VERSION "MK7 cluster DBC v2 — full reference for mk7-cluster-bench-controller"

NS_ :

BS_:

BU_: Tester Cluster Gateway EngineECU TCM ABS Airbag BCM EPS RX

VAL_TABLE_ Mode_OnOff 0 "OFF" 1 "ON" ;
VAL_TABLE_ Gear_Selector 1 "P" 2 "R" 3 "N" 4 "D" 5 "S" 6 "M" 0 "OFF" ;

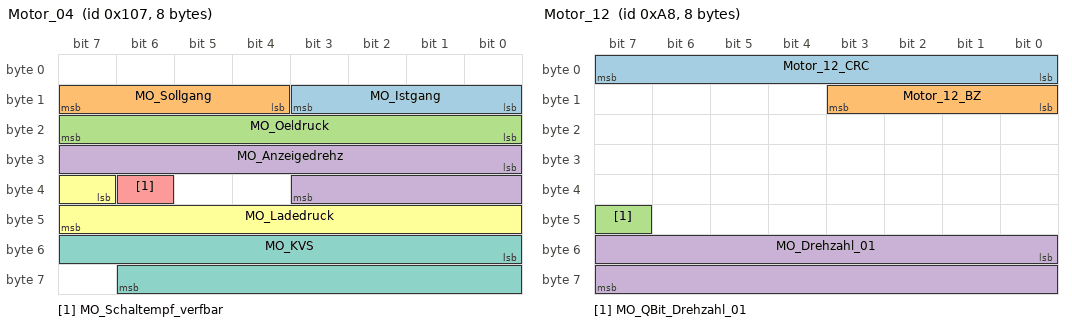
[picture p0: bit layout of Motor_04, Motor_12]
BO_ 263 Motor_04: 8 EngineECU
 SG_ MO_Istgang : 8|4@1+ (1,0) [0|15] "" Cluster
 SG_ MO_Sollgang : 12|4@1+ (1,0) [0|15] "" Cluster
 SG_ MO_Oeldruck : 16|8@1+ (0.04,0) [0|10] "Bar" Cluster
 SG_ MO_Anzeigedrehz : 24|12@1+ (3,0) [0|12282] "RPM" Cluster
 SG_ MO_Schaltempf_verfbar : 38|1@1+ (1,0) [0|1] "" Cluster
 SG_ MO_Ladedruck : 39|9@1+ (0.01,0) [0|5.1] "Bar" Cluster
 SG_ MO_KVS : 48|15@1+ (1,0) [0|32767] "uL" Cluster

BO_ 168 Motor_12: 8 EngineECU
 SG_ Motor_12_CRC : 0|8@1+ (1,0) [0|255] "" RX
 SG_ Motor_12_BZ : 8|4@1+ (1,0) [0|15] "" RX
 SG_ MO_QBit_Drehzahl_01 : 47|1@1+ (1,0) [0|1] "" RX
 SG_ MO_Drehzahl_01 : 48|16@1+ (0.25,0) [0|16383] "RPM" RX

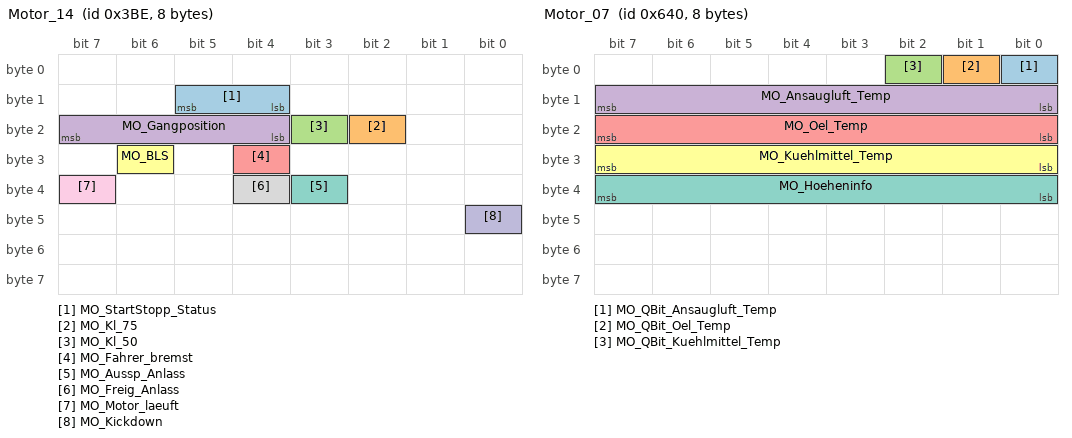
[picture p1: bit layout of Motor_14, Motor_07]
BO_ 958 Motor_14: 8 EngineECU
 SG_ MO_StartStopp_Status : 12|2@1+ (1,0) [0|3] "" Cluster
 SG_ MO_Kl_75 : 18|1@1+ (1,0) [0|1] "" Cluster
 SG_ MO_Kl_50 : 19|1@1+ (1,0) [0|1] "" Cluster
 SG_ MO_Gangposition : 20|4@1+ (1,0) [0|15] "" Cluster
 SG_ MO_Fahrer_bremst : 28|1@1+ (1,0) [0|1] "" Cluster
 SG_ MO_BLS : 30|1@1+ (1,0) [0|1] "" Cluster
 SG_ MO_Aussp_Anlass : 35|1@1+ (1,0) [0|1] "" Cluster
 SG_ MO_Freig_Anlass : 36|1@1+ (1,0) [0|1] "" Cluster
 SG_ MO_Motor_laeuft : 39|1@1+ (1,0) [0|1] "" Cluster
 SG_ MO_Kickdown : 40|1@1+ (1,0) [0|1] "" Cluster

BO_ 1600 Motor_07: 8 EngineECU
 SG_ MO_QBit_Ansaugluft_Temp : 0|1@1+ (1,0) [0|1] "" Cluster
 SG_ MO_QBit_Oel_Temp : 1|1@1+ (1,0) [0|1] "" Cluster
 SG_ MO_QBit_Kuehlmittel_Temp : 2|1@1+ (1,0) [0|1] "" Cluster
 SG_ MO_Ansaugluft_Temp : 8|8@1+ (0.75,-48) [-48|141.75] "DegC" Cluster
 SG_ MO_Oel_Temp : 16|8@1+ (1,-60) [-60|192] "DegC" Cluster
 SG_ MO_Kuehlmittel_Temp : 24|8@1+ (0.75,-48) [-48|141.75] "DegC" Cluster
 SG_ MO_Hoeheninfo : 32|8@1+ (0.00781,0) [0|1.98374] "" Cluster

BO_ 1607 Motor_09: 8 EngineECU
 SG_ MO_Coolant_Display : 0|8@1+ (1,0) [0|255] "" Cluster
 SG_ MO_E85_Sensor : 8|4@1+ (10,0) [0|100] "%" Cluster

BO_ 1601 Motor_Code_01: 8 EngineECU
 SG_ MotorCode01_CRC : 0|8@1+ (1,0) [0|255] "" Cluster
 SG_ MotorCode01_BZ : 8|4@1+ (1,0) [0|15] "" Cluster

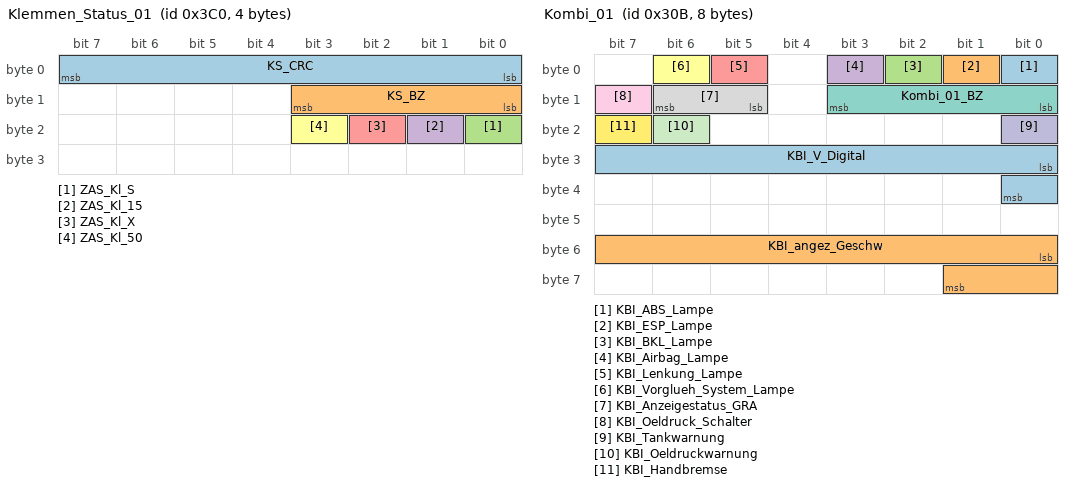
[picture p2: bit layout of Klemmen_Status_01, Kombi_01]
BO_ 960 Klemmen_Status_01: 4 Gateway
 SG_ KS_CRC : 0|8@1+ (1,0) [0|255] "" RX
 SG_ KS_BZ : 8|4@1+ (1,0) [0|15] "" RX
 SG_ ZAS_Kl_S : 16|1@1+ (1,0) [0|1] "" RX
 SG_ ZAS_Kl_15 : 17|1@1+ (1,0) [0|1] "" RX
 SG_ ZAS_Kl_X : 18|1@1+ (1,0) [0|1] "" RX
 SG_ ZAS_Kl_50 : 19|1@1+ (1,0) [0|1] "" RX

BO_ 779 Kombi_01: 8 Cluster
 SG_ KBI_ABS_Lampe : 0|1@1+ (1,0) [0|1] "" RX
 SG_ KBI_ESP_Lampe : 1|1@1+ (1,0) [0|1] "" RX
 SG_ KBI_BKL_Lampe : 2|1@1+ (1,0) [0|1] "" RX
 SG_ KBI_Airbag_Lampe : 3|1@1+ (1,0) [0|1] "" RX
 SG_ KBI_Lenkung_Lampe : 5|1@1+ (1,0) [0|1] "" RX
 SG_ KBI_Vorglueh_System_Lampe : 6|1@1+ (1,0) [0|1] "" RX
 SG_ Kombi_01_BZ : 8|4@1+ (1,0) [0|15] "" RX
 SG_ KBI_Anzeigestatus_GRA : 13|2@1+ (1,0) [0|3] "" RX
 SG_ KBI_Oeldruck_Schalter : 15|1@1+ (1,0) [0|1] "" RX
 SG_ KBI_Tankwarnung : 16|1@1+ (1,0) [0|1] "" RX
 SG_ KBI_Oeldruckwarnung : 22|1@1+ (1,0) [0|1] "" RX
 SG_ KBI_Handbremse : 23|1@1+ (1,0) [0|1] "" RX
 SG_ KBI_V_Digital : 24|9@1+ (1,0) [0|511] "km/h" RX
 SG_ KBI_angez_Geschw : 48|10@1+ (0.32,0) [0|325.12] "km/h" RX

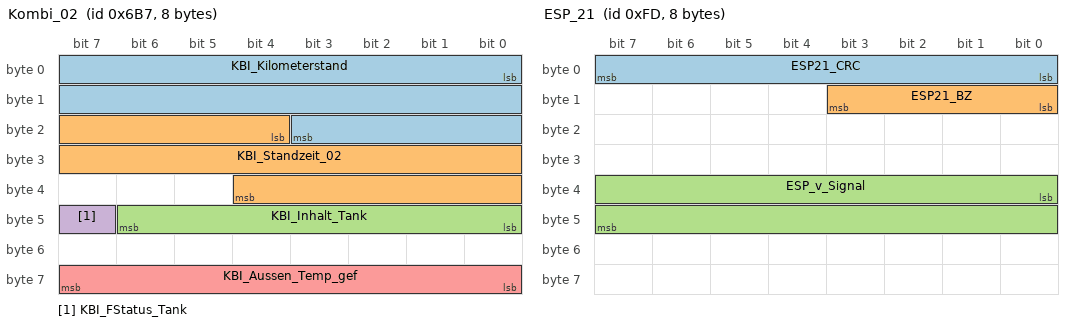
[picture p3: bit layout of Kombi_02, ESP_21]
BO_ 1719 Kombi_02: 8 Gateway
 SG_ KBI_Kilometerstand : 0|20@1+ (1,0) [0|1048573] "km" Cluster
 SG_ KBI_Standzeit_02 : 20|17@1+ (1,0) [0|131068] "s" Cluster
 SG_ KBI_Inhalt_Tank : 40|7@1+ (1,0) [0|125] "L" Cluster
 SG_ KBI_FStatus_Tank : 47|1@1+ (1,0) [0|1] "" Cluster
 SG_ KBI_Aussen_Temp_gef : 56|8@1+ (0.5,-50) [-50|75] "DegC" Cluster

BO_ 253 ESP_21: 8 ABS
 SG_ ESP21_CRC : 0|8@1+ (1,0) [0|255] "" RX
 SG_ ESP21_BZ : 8|4@1+ (1,0) [0|15] "" RX
 SG_ ESP_v_Signal : 32|16@1+ (0.01,0) [0|655.35] "km/h" RX

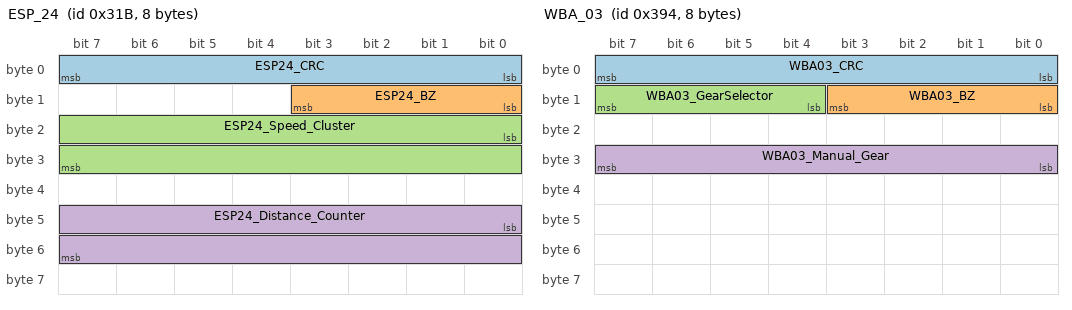
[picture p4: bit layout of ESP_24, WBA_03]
BO_ 795 ESP_24: 8 ABS
 SG_ ESP24_CRC : 0|8@1+ (1,0) [0|255] "" RX
 SG_ ESP24_BZ : 8|4@1+ (1,0) [0|15] "" RX
 SG_ ESP24_Speed_Cluster : 16|16@1+ (1,0) [0|65535] "" RX
 SG_ ESP24_Distance_Counter : 40|16@1+ (1,0) [0|65535] "" RX

BO_ 257 ESP_02: 8 ABS
 SG_ ESP02_CRC : 0|8@1+ (1,0) [0|255] "" RX
 SG_ ESP02_BZ : 8|4@1+ (1,0) [0|15] "" RX

BO_ 278 ESP_10: 8 ABS
 SG_ ESP10_CRC : 0|8@1+ (1,0) [0|255] "" RX
 SG_ ESP10_BZ : 8|4@1+ (1,0) [0|15] "" RX

BO_ 1629 ESP_20: 8 ABS
 SG_ ESP20_CRC : 0|8@1+ (1,0) [0|255] "" RX
 SG_ ESP20_BZ : 8|4@1+ (1,0) [0|15] "" RX

BO_ 798 TSK_07: 8 EngineECU
 SG_ TSK07_CRC : 0|8@1+ (1,0) [0|255] "" RX
 SG_ TSK07_BZ : 8|4@1+ (1,0) [0|15] "" RX

BO_ 810 LH_EPS_01: 8 EPS
 SG_ LHEPS01_CRC : 0|8@1+ (1,0) [0|255] "" RX
 SG_ LHEPS01_BZ : 8|4@1+ (1,0) [0|15] "" RX

BO_ 64 Airbag_01: 8 Airbag
 SG_ AB01_CRC : 0|8@1+ (1,0) [0|255] "" RX
 SG_ AB01_BZ : 8|4@1+ (1,0) [0|15] "" RX

BO_ 916 WBA_03: 8 Gateway
 SG_ WBA03_CRC : 0|8@1+ (1,0) [0|255] "" Cluster
 SG_ WBA03_BZ : 8|4@1+ (1,0) [0|15] "" Cluster
 SG_ WBA03_GearSelector : 12|4@1+ (1,0) [0|15] "" Cluster
 SG_ WBA03_Manual_Gear : 24|8@1+ (1,0) [0|9] "" Cluster

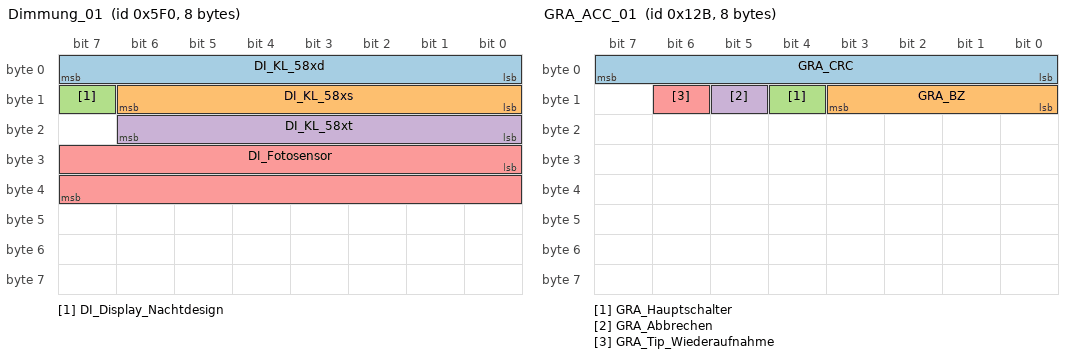
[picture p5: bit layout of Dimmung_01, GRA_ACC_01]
BO_ 1520 Dimmung_01: 8 Gateway
 SG_ DI_KL_58xd : 0|8@1+ (1,0) [0|253] "" RX
 SG_ DI_KL_58xs : 8|7@1+ (1,0) [0|100] "%" RX
 SG_ DI_Display_Nachtdesign : 15|1@1+ (1,0) [0|1] "" RX
 SG_ DI_KL_58xt : 16|7@1+ (1,0) [0|100] "%" RX
 SG_ DI_Fotosensor : 24|16@1+ (1,0) [0|65535] "" RX

BO_ 299 GRA_ACC_01: 8 Gateway
 SG_ GRA_CRC : 0|8@1+ (1,0) [0|255] "" RX
 SG_ GRA_BZ : 8|4@1+ (1,0) [0|15] "" RX
 SG_ GRA_Hauptschalter : 12|1@1+ (1,0) [0|1] "" RX
 SG_ GRA_Abbrechen : 13|1@1+ (1,0) [0|1] "" RX
 SG_ GRA_Tip_Wiederaufnahme : 14|1@1+ (1,0) [0|1] "" RX

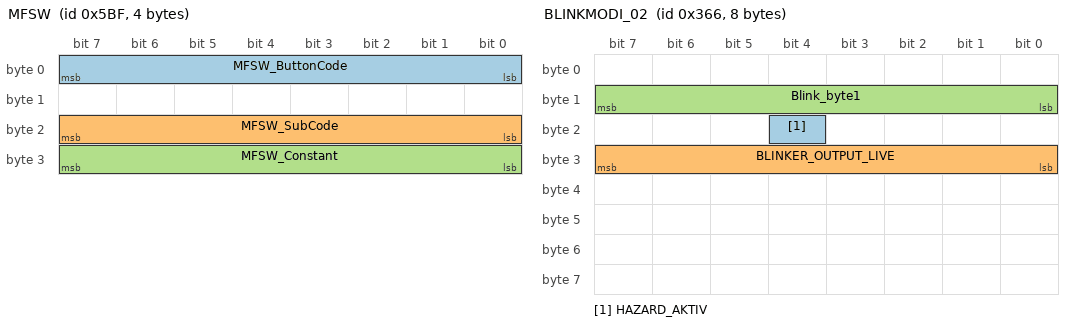
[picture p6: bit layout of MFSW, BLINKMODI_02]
BO_ 1471 MFSW: 4 Gateway
 SG_ MFSW_ButtonCode : 0|8@1+ (1,0) [0|255] "" Cluster
 SG_ MFSW_SubCode : 16|8@1+ (1,0) [0|255] "" Cluster
 SG_ MFSW_Constant : 24|8@1+ (1,0) [0|255] "" Cluster

BO_ 870 BLINKMODI_02: 8 BCM
 SG_ HAZARD_AKTIV : 20|1@1+ (1,0) [0|1] "" RX
 SG_ BLINKER_OUTPUT_LIVE : 24|8@1+ (1,0) [0|255] "" RX
 SG_ Blink_byte1 : 8|8@1+ (1,0) [0|255] "" RX

BO_ 1624 LICHT_VORNE_01: 8 BCM
 SG_ Front_HighBeam : 14|1@1+ (1,0) [0|1] "" RX
 SG_ Front_byte1_full : 8|8@1+ (1,0) [0|255] "" RX

BO_ 982 LICHT_HINTEN_01: 8 BCM
 SG_ Rear_byte1_full : 8|8@1+ (1,0) [0|255] "" RX

BO_ 1411 DOOR_STATUS_01: 8 BCM
 SG_ Door_byte0 : 0|8@1+ (1,0) [0|255] "" RX

BO_ 1505 OUTDOOR_TEMP_01: 8 Gateway
 SG_ Outdoor_byte1 : 8|8@1+ (0.5,-50) [-50|75] "DegC" RX

BO_ 1610 TPMS_01: 8 BCM
 SG_ TPMS_byte0 : 0|8@1+ (1,0) [0|255] "" RX

BO_ 1635 RKA_01: 8 BCM
 SG_ RKA_byte0 : 0|8@1+ (1,0) [0|255] "" RX

BO_ 1603 Einheiten_01: 8 Gateway
 SG_ Einheit_Speed_kmh_mph : 0|1@1+ (1,0) [0|1] "" Cluster
 SG_ Einheit_Temp_C_F : 1|1@1+ (1,0) [0|1] "" Cluster

BO_ 1716 VIN_01: 8 Gateway
 SG_ VIN_chunk_index : 0|8@1+ (1,0) [0|255] "" RX
 SG_ VIN_chunk_data : 8|56@1+ (1,0) [0|0] "" RX

CM_ BO_ 263 "Motor_04 — Engine ECU broadcast at ~50 Hz. CONFIRMED on 5G1 920 740B: bytes 3-4 LE drive cluster RPM tachometer (formula raw * 3 RPM/tick).";
CM_ BO_ 168 "Motor_12 — Engine torque + actual RPM. MQB CRC + counter required.";
CM_ BO_ 958 "Motor_14 — Engine status: gear position, engine_running flag, brake pedal, kickdown. MQB CRC + counter (constants 0xC0 from openpilot).";
CM_ BO_ 1600 "Motor_07 — Engine temps (intake, oil, COOLANT). byte 0 has QBit validity flags.";
CM_ BO_ 1607 "Motor_09 — CONFIRMED ON 5G1 920 740B AND validated against real vehicle CAN log (Alltrack 2017, May 2026). byte 0 = coolant value with linear mapping 0x80=50C → 0xED=130C (formula: temp_C = byte * 0.7339 - 43.94). Bytes 1-3 = magic 'FD FF 7F' confirmed identical on real vehicle. Bytes 4-6 = 00. byte 7 cycles between 0x13/0x18/0xC1/0x12 on real ECU (likely a counter or rolling sequence — but cluster accepts static 0xC1 too). Real ECU broadcasts at only ~2 Hz, so spoofing at 20+ Hz dominates the bus arbitration easily. Engine warmup logged: 0x86(54C) → 0xB3(87C) over 106 sec, perfectly linear with our formula. No CRC, no counter on byte 0/1.";
CM_ BO_ 1601 "Motor_Code_01 — Engine ECU heartbeat. CONFIRMED required as engine context for coolant override on 5G1 920 740B. MQB CRC with all-0x47 constants.";
CM_ BO_ 960 "Klemmen_Status_01 — CONFIRMED wakes the cluster on 5G1 920 740B (with hardware Kl.15 power on pin 16). 4 bytes. byte 2 bit 1 = ZAS_Kl_15 (ignition on). MQB CRC with all-0xC3 constants.";
CM_ BO_ 779 "Kombi_01 — sent BY THE CLUSTER per openpilot (NOT gateway). Reports current state of warning lamps, digital speed, displayed analog speed. Sending this TO the cluster has NO EFFECT — the cluster owns the message and uses its own internal state. To turn on a warning lamp, send the SOURCE message (e.g. ESP_21 with ABS error bit, Airbag_01 with crash flag, etc.).";
CM_ BO_ 1719 "Kombi_02 — Gateway → Cluster. Carries odometer (byte 0-3), fuel level liters (byte 5 low 7 bits, bit 7 = valid flag), outside temp (byte 7 with formula 0.5*x-50).";
CM_ BO_ 916 "WBA_03 — CONFIRMED on 5G1 920 740B: byte 1 high nibble drives MFA gear indicator. Values: 0x10=P, 0x20=R, 0x30=N, 0x40=D, 0x50=S, 0x60=Manual. byte 3 = M-gear digit (must be 0 for P/R/N/D otherwise cluster shows 'P4' etc.). MQB CRC.";
CM_ BO_ 1520 "Dimmung_01 — Gateway → Cluster. byte 1 = backlight target % (0-100). byte 2 = actual %. byte 1 bit 7 = night design.";
CM_ BO_ 1471 "MFSW (MultiFunction Steering Wheel) — 4 bytes. byte 0 = button code, byte 2 = sub-direction, byte 3 = 0x40 const. Per r00li: UP=06,_,01,40 / DOWN=06,_,0F,40 / LEFT=03,_,01,40 / RIGHT=02,_,01,40 / OK=07,_,01,40 / View=23,_,01,40. byte 1 = 0. NO CRC. Cluster ignores MFSW unless LH_EPS_01 (0x32A) heartbeat is also being broadcast (steering wheel 'alive' context).";
CM_ BO_ 64 "Airbag_01 — DELIBERATELY NOT TRANSMITTED by mk7-cluster-bench-controller (FORBIDDEN_IDS hard-block). Listed here for reference / passive reception only. Never spoof airbag system messages.";
CM_ BO_ 870 "BLINKMODI_02 — CONFIRMED hazards trigger from real-vehicle log (Alltrack 2017, May 2026 brake+trans.csv). byte 2 bit 4 = HAZARD_AKTIV (statique 1 quand bouton hazard activé). byte 3 = sortie ampoules en clignotement live (0x20 OFF / 0x3E ON, ~1.5 Hz). For 'Haldex disable when hazards' rule: read byte 2 bit 4 only — ignore byte 3 (it strobes). 6 transitions exactes detectées dans le log à t=41.63/44.83/46.38/49.58/50.43/53.63s = 3 ON/OFF cycles utilisateur.";
